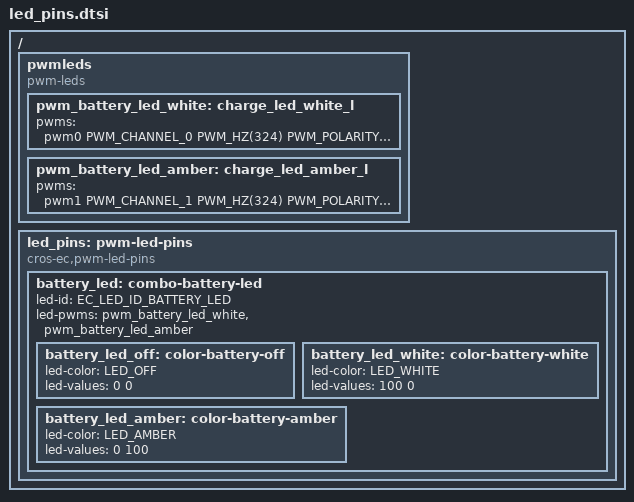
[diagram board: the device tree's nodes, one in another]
/* Copyright 2025 The ChromiumOS Authors
 * Use of this source code is governed by a BSD-style license that can be
 * found in the LICENSE file.
 */

 / {
	pwmleds {
		compatible = "pwm-leds";

		pwm_battery_led_white: charge_led_white_l {
			pwms = <&pwm0 PWM_CHANNEL_0 PWM_HZ(324)
				PWM_POLARITY_INVERTED>;
		};
		pwm_battery_led_amber: charge_led_amber_l {
			pwms = <&pwm1 PWM_CHANNEL_1 PWM_HZ(324)
				PWM_POLARITY_INVERTED>;
		};
	};

	led_pins: pwm-led-pins {
		compatible = "cros-ec,pwm-led-pins";

		battery_led: combo-battery-led {
			led-id = "EC_LED_ID_BATTERY_LED";
			led-pwms = <&pwm_battery_led_white
				    &pwm_battery_led_amber>;

			battery_led_off: color-battery-off {
				led-color = "LED_OFF";
				led-values = <0 0>;
			};

			battery_led_white: color-battery-white {
				led-color = "LED_WHITE";
				led-values = <100 0>;
			};

			battery_led_amber: color-battery-amber {
				led-color = "LED_AMBER";
				led-values = <0 100>;
			};
		};
	};
};
